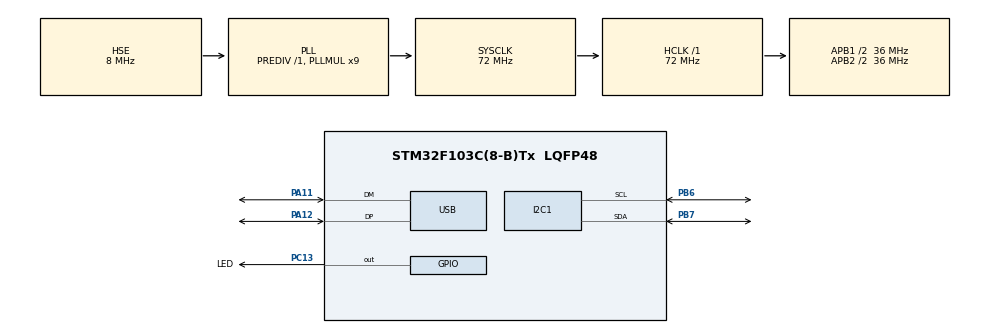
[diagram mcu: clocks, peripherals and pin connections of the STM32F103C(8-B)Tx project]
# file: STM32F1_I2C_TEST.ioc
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FREERTOS.Tasks01=defaultTask,0,128,StartDefaultTask,Default,NULL,Dynamic,NULL,NULL
FREERTOS.configUSE_TIMERS=0
I2C1.I2C_Mode=I2C_Fast
Mcu.Family=STM32F1
Mcu.Name=STM32F103C(8-B)Tx
Mcu.Package=LQFP48
NVIC.PriorityGroup=NVIC_PRIORITYGROUP_4
NVIC.TIM1_UP_IRQn=true\:15\:0\:false\:false\:true\:false\:false\:true\:true
NVIC.TimeBase=TIM1_UP_IRQn
NVIC.TimeBaseIP=TIM1
NVIC.USB_LP_CAN1_RX0_IRQn=true\:5\:0\:false\:false\:true\:true\:false\:true\:true
PA11.Mode=Device
PA11.Signal=USB_DM
PA12.Mode=Device
PA12.Signal=USB_DP
PB6.Mode=I2C
PB6.Signal=I2C1_SCL
PB7.Mode=I2C
PB7.Signal=I2C1_SDA
PC13-TAMPER-RTC.GPIO_Label=LED
PC13-TAMPER-RTC.GPIO_ModeDefaultOutputPP=GPIO_MODE_OUTPUT_OD
PC13-TAMPER-RTC.GPIO_PuPd=GPIO_NOPULL
PC13-TAMPER-RTC.PinState=GPIO_PIN_SET
PC13-TAMPER-RTC.Signal=GPIO_Output
PD0-OSC_IN.Mode=HSE-External-Oscillator
PD0-OSC_IN.Signal=RCC_OSC_IN
PD1-OSC_OUT.Mode=HSE-External-Oscillator
PD1-OSC_OUT.Signal=RCC_OSC_OUT
ProjectManager.HeapSize=0x200
ProjectManager.StackSize=0x400
ProjectManager.TargetToolchain=MDK-ARM V5.32
RCC.AHBFreq_Value=72000000
RCC.APB1CLKDivider=RCC_HCLK_DIV2
RCC.APB1Freq_Value=36000000
RCC.APB1TimFreq_Value=72000000
RCC.APB2CLKDivider=RCC_HCLK_DIV2
RCC.APB2Freq_Value=36000000
RCC.APB2TimFreq_Value=72000000
RCC.HCLKFreq_Value=72000000
RCC.PLLMUL=RCC_PLL_MUL9
RCC.SYSCLKFreq_VALUE=72000000
RCC.SYSCLKSource=RCC_SYSCLKSOURCE_PLLCLK
RCC.USBFreq_Value=48000000
RCC.USBPrescaler=RCC_USBCLKSOURCE_PLL_DIV1_5
USB_DEVICE.CLASS_NAME_FS=CDC
USB_DEVICE.VirtualMode=Cdc
USB_DEVICE.VirtualModeFS=Cdc_FS
VP_FREERTOS_VS_CMSIS_V1.Mode=CMSIS_V1
VP_SYS_VS_ND.Mode=No_Debug
VP_SYS_VS_tim1.Mode=TIM1
VP_USB_DEVICE_VS_USB_DEVICE_CDC_FS.Mode=CDC_FS
board=custom

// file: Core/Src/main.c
/* USER CODE BEGIN Header */
/**
  ******************************************************************************
  * @file           : main.c
  * @brief          : Main program body
  ******************************************************************************
  * @attention
  *
  * Copyright (c) 2022 STMicroelectronics.
  * All rights reserved.
  *
  * This software is licensed under terms that can be found in the LICENSE file
  * in the root directory of this software component.
  * If no LICENSE file comes with this software, it is provided AS-IS.
  *
  ******************************************************************************
  */
/* USER CODE END Header */
#include "main.h"
#include "cmsis_os.h"
#include "usb_device.h"

/* USER CODE BEGIN Includes */
#include "led.h"
/* USER CODE END Includes */

 I2C_HandleTypeDef hi2c1;

osThreadId defaultTaskHandle;
/* USER CODE BEGIN PV */
osThreadId ledTaskHandle;
/* USER CODE END PV */

void SystemClock_Config(void);
static void MX_GPIO_Init(void);
static void MX_I2C1_Init(void);
void StartDefaultTask(void const * argument);

int main(void)
{

  /* MCU Configuration--------------------------------------------------------*/

  /* Reset of all peripherals, Initializes the Flash interface and the Systick. */
  HAL_Init();

  /* Configure the system clock */
  SystemClock_Config();

  /* Initialize all configured peripherals */
  MX_GPIO_Init();
  MX_I2C1_Init();

  /* Create the thread(s) */
  /* definition and creation of defaultTask */
  osThreadDef(defaultTask, StartDefaultTask, osPriorityNormal, 0, 128);
  defaultTaskHandle = osThreadCreate(osThread(defaultTask), NULL);

  /* USER CODE BEGIN RTOS_THREADS */
  /* add threads, ... */
  osThreadDef(taskled, task_led, osPriorityNormal, 0, 128);
  ledTaskHandle = osThreadCreate(osThread(taskled), NULL);
  /* USER CODE END RTOS_THREADS */

  /* Start scheduler */
  osKernelStart();

  /* We should never get here as control is now taken by the scheduler */
  /* Infinite loop */
  while (1)
  {

  }
}

void SystemClock_Config(void)
{
  RCC_OscInitTypeDef RCC_OscInitStruct = {0};
  RCC_ClkInitTypeDef RCC_ClkInitStruct = {0};
  RCC_PeriphCLKInitTypeDef PeriphClkInit = {0};

  /** Initializes the RCC Oscillators according to the specified parameters
  * in the RCC_OscInitTypeDef structure.
  */
  RCC_OscInitStruct.OscillatorType = RCC_OSCILLATORTYPE_HSE;
  RCC_OscInitStruct.HSEState = RCC_HSE_ON;
  RCC_OscInitStruct.HSEPredivValue = RCC_HSE_PREDIV_DIV1;
  RCC_OscInitStruct.HSIState = RCC_HSI_ON;
  RCC_OscInitStruct.PLL.PLLState = RCC_PLL_ON;
  RCC_OscInitStruct.PLL.PLLSource = RCC_PLLSOURCE_HSE;
  RCC_OscInitStruct.PLL.PLLMUL = RCC_PLL_MUL9;
  if (HAL_RCC_OscConfig(&RCC_OscInitStruct) != HAL_OK)
  {
    Error_Handler();
  }

  /** Initializes the CPU, AHB and APB buses clocks
  */
  RCC_ClkInitStruct.ClockType = RCC_CLOCKTYPE_HCLK|RCC_CLOCKTYPE_SYSCLK
                              |RCC_CLOCKTYPE_PCLK1|RCC_CLOCKTYPE_PCLK2;
  RCC_ClkInitStruct.SYSCLKSource = RCC_SYSCLKSOURCE_PLLCLK;
  RCC_ClkInitStruct.AHBCLKDivider = RCC_SYSCLK_DIV1;
  RCC_ClkInitStruct.APB1CLKDivider = RCC_HCLK_DIV2;
  RCC_ClkInitStruct.APB2CLKDivider = RCC_HCLK_DIV2;

  if (HAL_RCC_ClockConfig(&RCC_ClkInitStruct, FLASH_LATENCY_2) != HAL_OK)
  {
    Error_Handler();
  }
  PeriphClkInit.PeriphClockSelection = RCC_PERIPHCLK_USB;
  PeriphClkInit.UsbClockSelection = RCC_USBCLKSOURCE_PLL_DIV1_5;
  if (HAL_RCCEx_PeriphCLKConfig(&PeriphClkInit) != HAL_OK)
  {
    Error_Handler();
  }
}

static void MX_I2C1_Init(void)
{

  hi2c1.Instance = I2C1;
  hi2c1.Init.ClockSpeed = 400000;
  hi2c1.Init.DutyCycle = I2C_DUTYCYCLE_2;
  hi2c1.Init.OwnAddress1 = 0;
  hi2c1.Init.AddressingMode = I2C_ADDRESSINGMODE_7BIT;
  hi2c1.Init.DualAddressMode = I2C_DUALADDRESS_DISABLE;
  hi2c1.Init.OwnAddress2 = 0;
  hi2c1.Init.GeneralCallMode = I2C_GENERALCALL_DISABLE;
  hi2c1.Init.NoStretchMode = I2C_NOSTRETCH_DISABLE;
  if (HAL_I2C_Init(&hi2c1) != HAL_OK)
  {
    Error_Handler();
  }

}

static void MX_GPIO_Init(void)
{
  GPIO_InitTypeDef GPIO_InitStruct = {0};

  /* GPIO Ports Clock Enable */
  __HAL_RCC_GPIOC_CLK_ENABLE();
  __HAL_RCC_GPIOD_CLK_ENABLE();
  __HAL_RCC_GPIOA_CLK_ENABLE();
  __HAL_RCC_GPIOB_CLK_ENABLE();

  /*Configure GPIO pin Output Level */
  HAL_GPIO_WritePin(LED_GPIO_Port, LED_Pin, GPIO_PIN_SET);

  /*Configure GPIO pin : LED_Pin */
  GPIO_InitStruct.Pin = LED_Pin;
  GPIO_InitStruct.Mode = GPIO_MODE_OUTPUT_OD;
  GPIO_InitStruct.Pull = GPIO_NOPULL;
  GPIO_InitStruct.Speed = GPIO_SPEED_FREQ_LOW;
  HAL_GPIO_Init(LED_GPIO_Port, &GPIO_InitStruct);

  /*Configure GPIO pins : PC14 PC15 */
  GPIO_InitStruct.Pin = GPIO_PIN_14|GPIO_PIN_15;
  GPIO_InitStruct.Mode = GPIO_MODE_ANALOG;
  HAL_GPIO_Init(GPIOC, &GPIO_InitStruct);

  /*Configure GPIO pins : PA0 PA1 PA2 PA3
                           PA4 PA5 PA6 PA7
                           PA8 PA9 PA10 PA13
                           PA14 PA15 */
  GPIO_InitStruct.Pin = GPIO_PIN_0|GPIO_PIN_1|GPIO_PIN_2|GPIO_PIN_3
                          |GPIO_PIN_4|GPIO_PIN_5|GPIO_PIN_6|GPIO_PIN_7
                          |GPIO_PIN_8|GPIO_PIN_9|GPIO_PIN_10|GPIO_PIN_13
                          |GPIO_PIN_14|GPIO_PIN_15;
  GPIO_InitStruct.Mode = GPIO_MODE_ANALOG;
  HAL_GPIO_Init(GPIOA, &GPIO_InitStruct);

  /*Configure GPIO pins : PB0 PB1 PB2 PB10
                           PB11 PB12 PB13 PB14
                           PB15 PB3 PB4 PB5
                           PB8 PB9 */
  GPIO_InitStruct.Pin = GPIO_PIN_0|GPIO_PIN_1|GPIO_PIN_2|GPIO_PIN_10
                          |GPIO_PIN_11|GPIO_PIN_12|GPIO_PIN_13|GPIO_PIN_14
                          |GPIO_PIN_15|GPIO_PIN_3|GPIO_PIN_4|GPIO_PIN_5
                          |GPIO_PIN_8|GPIO_PIN_9;
  GPIO_InitStruct.Mode = GPIO_MODE_ANALOG;
  HAL_GPIO_Init(GPIOB, &GPIO_InitStruct);

}

void StartDefaultTask(void const * argument)
{
  /* init code for USB_DEVICE */
  MX_USB_DEVICE_Init();
  for(;;)
  {
    osDelay(1);
  }
}

void HAL_TIM_PeriodElapsedCallback(TIM_HandleTypeDef *htim)
{
  if (htim->Instance == TIM1) {
    HAL_IncTick();
  }
}

void Error_Handler(void)
{
  __disable_irq();
  while (1)
  {
  }
}
